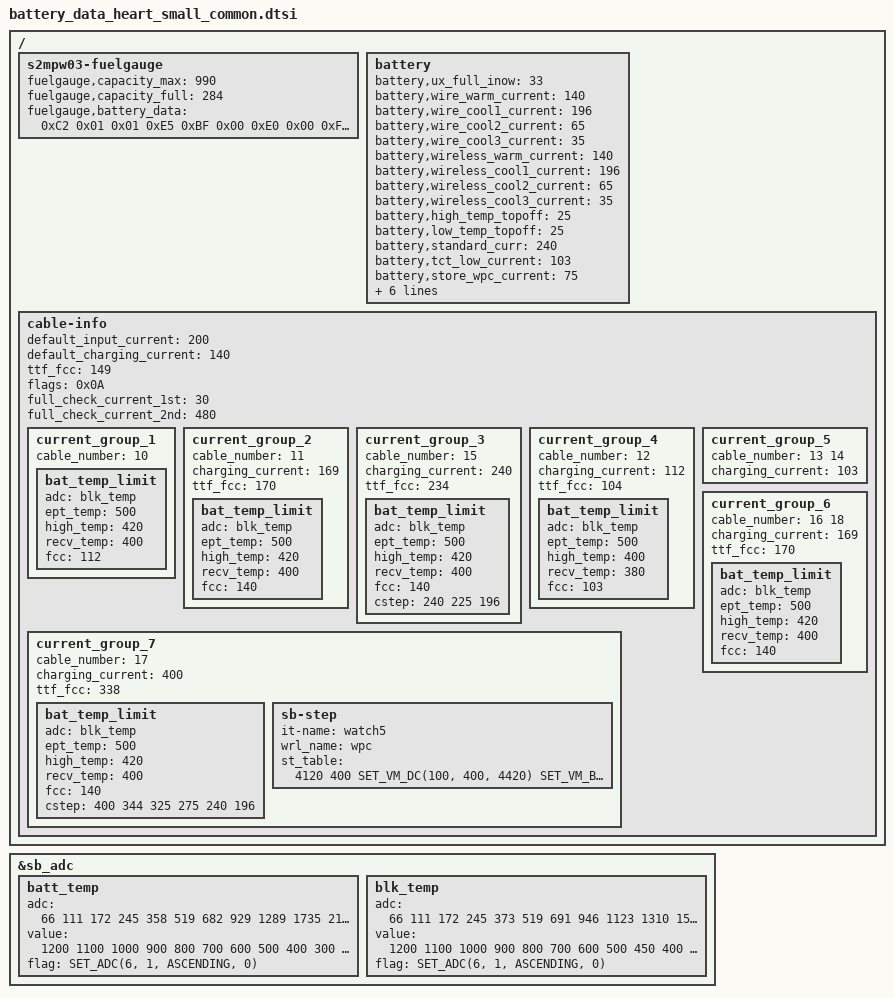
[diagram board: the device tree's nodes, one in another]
/*
 * SAMSUNG EXYNOS5515 board device tree source
 *
 * Copyright (c) 2021 Samsung Electronics Co., Ltd.
 *		http://www.samsung.com
 *
 * This program is free software; you can redistribute it and/or modify
 * it under the terms of the GNU General Public License version 2 as
 * published by the Free Software Foundation.
 */

#include "battery_data_heart_common.dtsi"

&sb_adc {
	batt_temp {
		adc = <
				66 111 172 245 358 519 682 929 1289 1735
				2143 2633 3050 3416 3664
			>;

		value = <
				1200 1100 1000 900 800 700 600 500 400 300
				200 100 0 (-100) (-200)
			>;

		flag = <SET_ADC(6, 1, ASCENDING, 0)>;
	};

	blk_temp {
		adc = <
				66 111 172 245 373 519 691 946 1123
				1310 1515 1757 2153 2644 3056 3422 3686 3799 4000
			>;

		value = <
				1200 1100 1000 900 800 700 600 500 450
				400 350 300 200 100 0 (-100) (-200) (-300) (-400)
			>;

		flag = <SET_ADC(6, 1, ASCENDING, 0)>;
	};
};

/ {
	fragment@battery {
		target-path = "/";
		__overlay__ {
			s2mpw03-fuelgauge {
				fuelgauge,capacity_max = <990>;
				fuelgauge,capacity_full = <284>;

				fuelgauge,battery_data = /bits/ 8 <
					/* 4.42V */
					/* table1 */
					0xC2 0x01 0x01 0xE5 0xBF
					/* table2 */
					0x00 0xE0 0x00
					/* model_param1 */
					0xF9 0x0B 0x86 0x0B 0x12 0x0B 0x9F 0x0A 0x24 0x0A
					0xA5 0x09 0x29 0x09 0xB5 0x08 0x4A 0x08 0xE7 0x07
					0x66 0x07 0x11 0x07 0xD4 0x06 0xA3 0x06 0x7B 0x06
					0x57 0x06 0x23 0x06 0xF3 0x05 0xB4 0x05 0x8F 0x05
					0xFE 0x04 0x57 0x02 0xDC 0x08 0x6E 0x08 0x00 0x08
					0x92 0x07 0x24 0x07 0xB6 0x06 0x48 0x06 0xDA 0x05
					0x6C 0x05 0xFE 0x04 0x90 0x04 0x22 0x04 0xB4 0x03
					0x46 0x03 0xD8 0x02 0x6A 0x02 0xFC 0x01 0x8E 0x01
					0x20 0x01 0xB2 0x00 0x44 0x00 0xEE 0x0F
					/* model_param2 */
					0xB6 0xB6 0xB6 0xB2 0xAD 0xA7 0xAA 0xAC 0xA8 0xA7
					0xA2 0xA2 0xA8 0xAD 0xB1 0xB2 0xBB 0xBA 0xBF 0xCB
					0xDB 0xE6

					/* 4.4V */
					/* table1 */
					0xA1 0xFE 0x00 0x90 0xC2
					/* table2 */
					0x00 0xF0 0x00
					/* model_param1 */
					0x68 0x0B 0xFC 0x0A 0x91 0x0A 0x20 0x0A 0xAB 0x09
					0x38 0x09 0xCC 0x08 0x68 0x08 0x0A 0x08 0x9E 0x07
					0x3C 0x07 0xF8 0x06 0xC4 0x06 0x99 0x06 0x74 0x06
					0x52 0x06 0x22 0x06 0xF6 0x05 0xBC 0x05 0x96 0x05
					0x28 0x05 0xD8 0x02 0x66 0x08 0x00 0x08 0x9A 0x07
					0x33 0x07 0xCD 0x06 0x66 0x06 0x00 0x06 0x9A 0x05
					0x33 0x05 0xCD 0x04 0x66 0x04 0x00 0x04 0x9A 0x03
					0x33 0x03 0xCD 0x02 0x66 0x02 0x00 0x02 0x9A 0x01
					0x33 0x01 0xCD 0x00 0x66 0x00 0x00 0x00
					/* model_param2 */
					0xB6 0xB6 0xB6 0xB2 0xAD 0xA7 0xAA 0xAC 0xA8 0xA7
					0xA2 0xA2 0xA8 0xAD 0xB1 0xB2 0xBB 0xBA 0xBF 0xCB
					0xDB 0xE6

					/* 4.38V */
					/* table1 */
					0xA1 0xFA 0x00 0x90 0xC2
					/* table2 */
					0x00 0xF0 0x00
					/* model_param1 */
					0x44 0x0B 0xD9 0x0A 0x6D 0x0A 0xFC 0x09 0x8A 0x09
					0x1A 0x09 0xB1 0x08 0x50 0x08 0xF6 0x07 0x86 0x07
					0x2E 0x07 0xEF 0x06 0xBD 0x06 0x94 0x06 0x71 0x06
					0x4D 0x06 0x1E 0x06 0xF3 0x05 0xB9 0x05 0x95 0x05
					0x26 0x05 0xD9 0x02 0x66 0x08 0x00 0x08 0x9A 0x07
					0x33 0x07 0xCD 0x06 0x66 0x06 0x00 0x06 0x9A 0x05
					0x33 0x05 0xCD 0x04 0x66 0x04 0x00 0x04 0x9A 0x03
					0x33 0x03 0xCD 0x02 0x66 0x02 0x00 0x02 0x9A 0x01
					0x33 0x01 0xCD 0x00 0x66 0x00 0x00 0x00
					/* model_param2 */
					0xB6 0xB6 0xB6 0xB2 0xAD 0xA7 0xAA 0xAC 0xA8 0xA7
					0xA2 0xA2 0xA8 0xAD 0xB1 0xB2 0xBB 0xBA 0xBF 0xCB
					0xDB 0xE6

					/* 4.36V */
					/* table1 */
					0xA1 0xF5 0x00 0x90 0xC2
					/* table2 */
					0x00 0xF0 0x00
					/* model_param1 */
					0x1E 0x0B 0xB2 0x0A 0x46 0x0A 0xD6 0x09 0x66 0x09
					0xFB 0x08 0x96 0x08 0x38 0x08 0xDF 0x07 0x6C 0x07
					0x1E 0x07 0xE5 0x06 0xB6 0x06 0x8F 0x06 0x6D 0x06
					0x48 0x06 0x1A 0x06 0xEE 0x05 0xB6 0x05 0x94 0x05
					0x23 0x05 0xD8 0x02 0x66 0x08 0x00 0x08 0x9A 0x07
					0x33 0x07 0xCD 0x06 0x66 0x06 0x00 0x06 0x9A 0x05
					0x33 0x05 0xCD 0x04 0x66 0x04 0x00 0x04 0x9A 0x03
					0x33 0x03 0xCD 0x02 0x66 0x02 0x00 0x02 0x9A 0x01
					0x33 0x01 0xCD 0x00 0x66 0x00 0x00 0x00
					/* model_param2 */
					0xB6 0xB6 0xB6 0xB2 0xAD 0xA7 0xAA 0xAC 0xA8 0xA7
					0xA2 0xA2 0xA8 0xAD 0xB1 0xB2 0xBB 0xBA 0xBF 0xCB
					0xDB 0xE6

					/* 4.31V */
					/* table1 */
					0xA1 0xEA 0x00 0x90 0xC2
					/* table2 */
					0x00 0xF0 0x00
					/* model_param1 */
					0xB5 0x0A 0x4A 0x0A 0xE0 0x09 0x76 0x09 0x0F 0x09
					0xAD 0x08 0x52 0x08 0xFD 0x07 0x97 0x07 0x3E 0x07
					0xFE 0x06 0xCD 0x06 0xA3 0x06 0x81 0x06 0x62 0x06
					0x3B 0x06 0x10 0x06 0xE4 0x05 0xB0 0x05 0x91 0x05
					0x1D 0x05 0xD9 0x02 0x66 0x08 0x00 0x08 0x9A 0x07
					0x33 0x07 0xCD 0x06 0x66 0x06 0x00 0x06 0x9A 0x05
					0x33 0x05 0xCD 0x04 0x66 0x04 0x00 0x04 0x9A 0x03
					0x33 0x03 0xCD 0x02 0x66 0x02 0x00 0x02 0x9A 0x01
					0x33 0x01 0xCD 0x00 0x66 0x00 0x00 0x00
					/* model_param2 */
					0xB6 0xB6 0xB6 0xB2 0xAD 0xA7 0xAA 0xAC 0xA8 0xA7
					0xA2 0xA2 0xA8 0xAD 0xB1 0xB2 0xBB 0xBA 0xBF 0xCB
					0xDB 0xE6
				>;
			};

			battery {
				battery,ux_full_inow = <33>;

				battery,wire_warm_current = <140>;	/* 0.5C */
				battery,wire_cool1_current = <196>;	/* 0.71C */
				battery,wire_cool2_current = <65>;	/* 0.24C */
				battery,wire_cool3_current = <35>;	/* 0.16C */

				battery,wireless_warm_current = <140>;	/* 0.5C */
				battery,wireless_cool1_current = <196>;	/* 0.71C */
				battery,wireless_cool2_current = <65>;	/* 0.24C */
				battery,wireless_cool3_current = <35>;	/* 0.16C */

				battery,high_temp_topoff = <25>;	/* 0.05C */
				battery,low_temp_topoff = <25>;		/* 0.05C */

				battery,standard_curr = <240>;
				battery,tct_low_current = <103>;
				battery,store_wpc_current = <75>;
				battery,age_data_cc_cv_threshold = <4150 4150 4150 4150 4150>;

				battery,battery_full_capacity = <284>;
				battery,ttf_capacity = <284>;
				battery,cv_data = <
					315	530	2935
					304	599	2780
					289	643	2588
					266	685	2449
					246	704	2380
					229	722	2310
					210	785	2033
					195	831	1824
					163	858	1685
					149	870	1616
					138	880	1535
					115	902	1373
					100	923	1199
					95	931	1115
					87	944	990
					76	954	850
					67	966	711
					53	979	487
					42	989	279
					31	1000	0
					>;
			};

			/* sec_battery_cable
			 *   0	UNKNOWN,
			 *   1	NONE,
			 *   2	TA,
			 *   3	USB,
			 *   4	UARTOFF,
			 *   5	RESERVED,
			 *   6	RESERVED,
			 *   7	RESERVED,
			 *   8	RESERVED,
			 *   9	RESERVED,
			 *  10	WRL,
			 *  11	INBOX_WRL,
			 *  12	D2D_WRL,
			 *  13	INCOMP_WRL,
			 *  14	ERR_WRL,
			 *  15	FM_WRL,
			 *  16	AUTH_WRL_2W,
 			 *  17	AUTH_WRL_5W,
 			 *  18	ERR_AUTH_WRL,
			 */
			cable-info {
				default_input_current = <200>;
				default_charging_current = <140>;	/* 0.5C */
				ttf_fcc = <149>;
				flags = <0x0A>;

				full_check_current_1st = <30>;
				full_check_current_2nd = <480>;	/* time: 8min */

				current_group_1 {
					cable_number = <10>;

					bat_temp_limit {
						adc = "blk_temp";
						ept_temp = <500>;
						high_temp = <420>;
						recv_temp = <400>;
						fcc = <112>;
					};
				};

				current_group_2 {
					cable_number = <11>;
					charging_current = <169>;	/* 0.6C */
					ttf_fcc = <170>;

					bat_temp_limit {
						adc = "blk_temp";
						ept_temp = <500>;
						high_temp = <420>;
						recv_temp = <400>;
						fcc = <140>;
					};
				};

				current_group_3 {
					cable_number = <15>;
					charging_current = <240>;	/* 0.87C */
					ttf_fcc = <234>;

					bat_temp_limit {
						adc = "blk_temp";
						ept_temp = <500>;
						high_temp = <420>;
						recv_temp = <400>;
						fcc = <140>;
						cstep = <240 225 196>; /* 0.87C ~ 0.71C */
					};
				};

				current_group_4 {
					cable_number = <12>;
					charging_current = <112>;
					ttf_fcc = <104>;

					bat_temp_limit {
						adc = "blk_temp";
						ept_temp = <500>;
						high_temp = <400>;
						recv_temp = <380>;
						fcc = <103>;
					};
				};

				current_group_5 {
					cable_number = <13 14>;
					charging_current = <103>;
				};

				current_group_6 {
					cable_number = <16 18>;
					charging_current = <169>;	/* 0.6C */
					ttf_fcc = <170>;

					bat_temp_limit {
						adc = "blk_temp";
						ept_temp = <500>;
						high_temp = <420>;
						recv_temp = <400>;
						fcc = <140>;  /* 0.5C */
					};
				};

				current_group_7 {
					cable_number = <17>;
					charging_current = <400>;	/* 1.45C */
					ttf_fcc = <338>;

					bat_temp_limit {
						adc = "blk_temp";
						ept_temp = <500>;
						high_temp = <420>;
						recv_temp = <400>;
						fcc = <140>; /* 0.5C */
						cstep = <400 344 325 275 240 196>; /* 1.45C ~ 0.71C */
					};

					sb-step {
						it-name = "watch5";

						wrl_name = "wpc";
						st_table = < /* 1.45C 1.25C 0.87C */
							/* fv	fcc		cc							cv							cc_cur	cv_cur */
							4120	400		SET_VM_DC(100, 400, 4420)	SET_VM_BT(4420, 300, 100)	400		404
							4280	344		SET_VM_DC(100, 344, 4580)	SET_VM_BT(4580, 300, 100)	344		300
							MAX_FV	240		SET_VM_DC(100, 240, 4700)	SET_VM_FX(4700, 100)		240		0
							>;
					};
				};
			};
		};
	};
};

